# ATSAMV71J21 device description
Architecture: CORTEX-M7; Family: SAMV; Series: SAMV71
Registers are 32-bit, read-write, no defined reset value unless marked. A register's access mark holds for its fields unless they carry their own. Offsets are from the block's base; [hi:lo] are bit positions; {n}, {i} and the like mark numbered series.

## ISI — Image Sensor Interface
Instances: ISI 0x4004C000
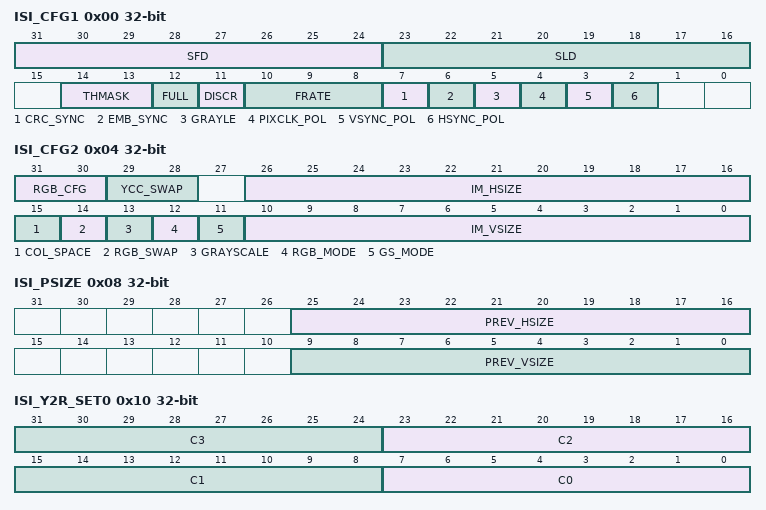
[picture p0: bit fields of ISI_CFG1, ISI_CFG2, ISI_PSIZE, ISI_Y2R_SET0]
0x00 ISI_CFG1 — ISI Configuration 1 Register
  [31:24] SFD — Start of Frame Delay
  [23:16] SLD — Start of Line Delay
  [14:13] THMASK — Threshold Mask
    0=BEATS_4 (Only 4 beats AHB burst allowed); 1=BEATS_8 (Only 4 and 8 beats AHB burst allowed); 2=BEATS_16 (4, 8 and 16 beats AHB burst allowed)
  [12] FULL — Full Mode is Allowed
  [11] DISCR — Disable Codec Request
  [10:8] FRATE — Frame Rate [0..7]
  [7] CRC_SYNC — Embedded Synchronization Correction
  [6] EMB_SYNC — Embedded Synchronization
  [5] GRAYLE — Grayscale Little Endian
  [4] PIXCLK_POL — Pixel Clock Polarity
  [3] VSYNC_POL — Vertical Synchronization Polarity
  [2] HSYNC_POL — Horizontal Synchronization Polarity
0x04 ISI_CFG2 — ISI Configuration 2 Register
  [31:30] RGB_CFG — RGB Pixel Mapping Configuration
    0=DEFAULT (Byte 0 R/G(MSB)Byte 1 G(LSB)/BByte 2 R/G(MSB)Byte 3 G(LSB)/B); 1=MODE1 (Byte 0 B/G(MSB)Byte 1 G(LSB)/RByte 2 B/G(MSB)Byte 3 G(LSB)/R); 2=MODE2 (Byte 0 G(LSB)/RByte 1 B/G(MSB)Byte 2 G(LSB)/RByte 3 B/G(MSB)); 3=MODE3 (Byte 0 G(LSB)/BByte 1 R/G(MSB)Byte 2 G(LSB)/BByte 3 R/G(MSB))
  [29:28] YCC_SWAP — YCrCb Format Swap Mode
    0=DEFAULT (Byte 0 Cb(i)Byte 1 Y(i)Byte 2 Cr(i)Byte 3 Y(i+1)); 1=MODE1 (Byte 0 Cr(i)Byte 1 Y(i)Byte 2 Cb(i)Byte 3 Y(i+1)); 2=MODE2 (Byte 0 Y(i)Byte 1 Cb(i)Byte 2 Y(i+1)Byte 3 Cr(i)); 3=MODE3 (Byte 0 Y(i)Byte 1 Cr(i)Byte 2 Y(i+1)Byte 3 Cb(i))
  [26:16] IM_HSIZE — Horizontal Size of the Image Sensor [0..2047]
  [15] COL_SPACE — Color Space for the Image Data
  [14] RGB_SWAP — RGB Format Swap Mode
  [13] GRAYSCALE — Grayscale Mode Format Enable
  [12] RGB_MODE — RGB Input Mode
  [11] GS_MODE — Grayscale Pixel Format Mode
  [10:0] IM_VSIZE — Vertical Size of the Image Sensor [0..2047]
0x08 ISI_PSIZE — ISI Preview Size Register
  [25:16] PREV_HSIZE — Horizontal Size for the Preview Path
  [9:0] PREV_VSIZE — Vertical Size for the Preview Path
0x0C ISI_PDECF — ISI Preview Decimation Factor Register
  [7:0] DEC_FACTOR — Decimation Factor
0x10 ISI_Y2R_SET0 — ISI Color Space Conversion YCrCb To RGB Set 0 Register
  [8n+7:8n] C{n} (n=0..3) — Color Space Conversion Matrix Coefficient C{n}
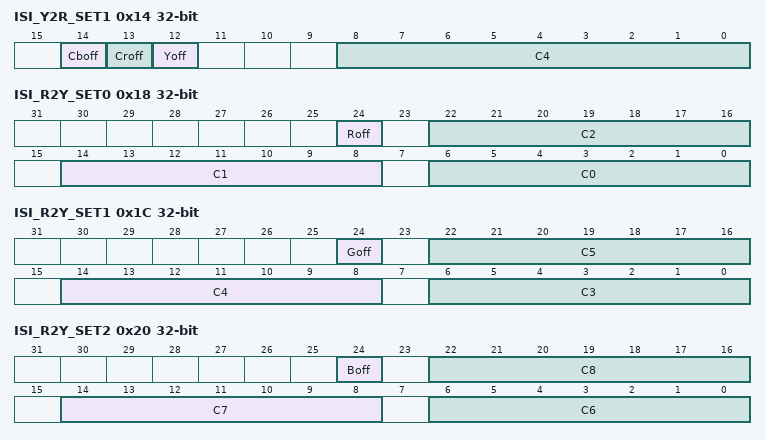
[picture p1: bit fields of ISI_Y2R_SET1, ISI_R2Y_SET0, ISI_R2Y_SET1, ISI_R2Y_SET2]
0x14 ISI_Y2R_SET1 — ISI Color Space Conversion YCrCb To RGB Set 1 Register
  [14] Cboff — Color Space Conversion Blue Chrominance Default Offset
  [13] Croff — Color Space Conversion Red Chrominance Default Offset
  [12] Yoff — Color Space Conversion Luminance Default Offset
  [8:0] C4 — Color Space Conversion Matrix Coefficient C4
0x18 ISI_R2Y_SET0 — ISI Color Space Conversion RGB To YCrCb Set 0 Register
  [24] Roff — Color Space Conversion Red Component Offset
  [22:16] C2 — Color Space Conversion Matrix Coefficient C2
  [14:8] C1 — Color Space Conversion Matrix Coefficient C1
  [6:0] C0 — Color Space Conversion Matrix Coefficient C0
0x1C ISI_R2Y_SET1 — ISI Color Space Conversion RGB To YCrCb Set 1 Register
  [24] Goff — Color Space Conversion Green Component Offset
  [22:16] C5 — Color Space Conversion Matrix Coefficient C5
  [14:8] C4 — Color Space Conversion Matrix Coefficient C4
  [6:0] C3 — Color Space Conversion Matrix Coefficient C3
0x20 ISI_R2Y_SET2 — ISI Color Space Conversion RGB To YCrCb Set 2 Register
  [24] Boff — Color Space Conversion Blue Component Offset
  [22:16] C8 — Color Space Conversion Matrix Coefficient C8
  [14:8] C7 — Color Space Conversion Matrix Coefficient C7
  [6:0] C6 — Color Space Conversion Matrix Coefficient C6
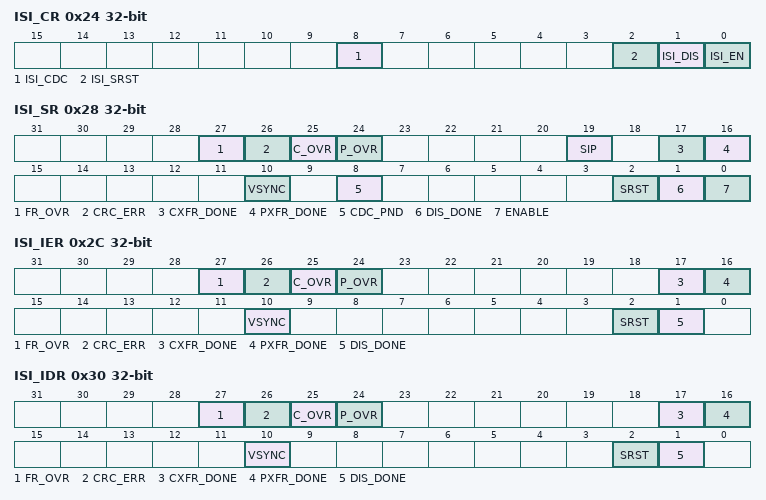
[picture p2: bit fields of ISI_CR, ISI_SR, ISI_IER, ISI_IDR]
0x24 ISI_CR wo — ISI Control Register
  [8] ISI_CDC — ISI Codec Request
  [2] ISI_SRST — ISI Software Reset Request
  [1] ISI_DIS — ISI Module Disable Request
  [0] ISI_EN — ISI Module Enable Request
0x28 ISI_SR ro — ISI Status Register
  [27] FR_OVR — Frame Rate Overrun (cleared on read)
  [26] CRC_ERR — CRC Synchronization Error (cleared on read)
  [25] C_OVR — Codec Datapath Overflow (cleared on read)
  [24] P_OVR — Preview Datapath Overflow (cleared on read)
  [19] SIP — Synchronization in Progress
  [17] CXFR_DONE — Codec DMA Transfer has Terminated (cleared on read)
  [16] PXFR_DONE — Preview DMA Transfer has Terminated (cleared on read)
  [10] VSYNC — Vertical Synchronization (cleared on read)
  [8] CDC_PND — Pending Codec Request
  [2] SRST — Module Software Reset Request has Terminated (cleared on read)
  [1] DIS_DONE — Module Disable Request has Terminated (cleared on read)
  [0] ENABLE — Module Enable
0x2C ISI_IER wo (atomic set of ISI_IMR) — ISI Interrupt Enable Register
  [27] FR_OVR — Frame Rate Overflow Interrupt Enable
  [26] CRC_ERR — Embedded Synchronization CRC Error Interrupt Enable
  [25] C_OVR — Codec Datapath Overflow Interrupt Enable
  [24] P_OVR — Preview Datapath Overflow Interrupt Enable
  [17] CXFR_DONE — Codec DMA Transfer Done Interrupt Enable
  [16] PXFR_DONE — Preview DMA Transfer Done Interrupt Enable
  [10] VSYNC — Vertical Synchronization Interrupt Enable
  [2] SRST — Software Reset Interrupt Enable
  [1] DIS_DONE — Disable Done Interrupt Enable
0x30 ISI_IDR wo (atomic clear of ISI_IMR) — ISI Interrupt Disable Register
  [27] FR_OVR — Frame Rate Overflow Interrupt Disable
  [26] CRC_ERR — Embedded Synchronization CRC Error Interrupt Disable
  [25] C_OVR — Codec Datapath Overflow Interrupt Disable
  [24] P_OVR — Preview Datapath Overflow Interrupt Disable
  [17] CXFR_DONE — Codec DMA Transfer Done Interrupt Disable
  [16] PXFR_DONE — Preview DMA Transfer Done Interrupt Disable
  [10] VSYNC — Vertical Synchronization Interrupt Disable
  [2] SRST — Software Reset Interrupt Disable
  [1] DIS_DONE — Disable Done Interrupt Disable
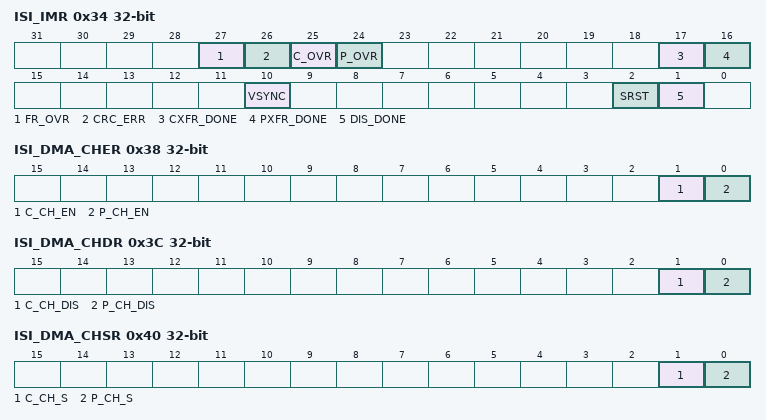
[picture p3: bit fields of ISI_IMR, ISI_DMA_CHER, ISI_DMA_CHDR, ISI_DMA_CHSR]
0x34 ISI_IMR ro (atomic read) — ISI Interrupt Mask Register
  [27] FR_OVR — Frame Rate Overrun
  [26] CRC_ERR — CRC Synchronization Error
  [25] C_OVR — Codec FIFO Overflow
  [24] P_OVR — Preview FIFO Overflow
  [17] CXFR_DONE — Codec DMA Transfer Completed
  [16] PXFR_DONE — Preview DMA Transfer Completed
  [10] VSYNC — Vertical Synchronization
  [2] SRST — Software Reset Completed
  [1] DIS_DONE — Module Disable Operation Completed
0x38 ISI_DMA_CHER wo (atomic set of ISI_DMA_CHSR) — DMA Channel Enable Register
  [1] C_CH_EN — Codec Channel Enable
  [0] P_CH_EN — Preview Channel Enable
0x3C ISI_DMA_CHDR wo (atomic clear of ISI_DMA_CHSR) — DMA Channel Disable Register
  [1] C_CH_DIS — Codec Channel Disable Request
  [0] P_CH_DIS — Preview Channel Disable Request
0x40 ISI_DMA_CHSR ro — DMA Channel Status Register
  [1] C_CH_S — Code DMA Channel Status
  [0] P_CH_S — Preview DMA Channel Status
0x44 ISI_DMA_P_ADDR — DMA Preview Base Address Register
  [31:2] P_ADDR — Preview Image Base Address
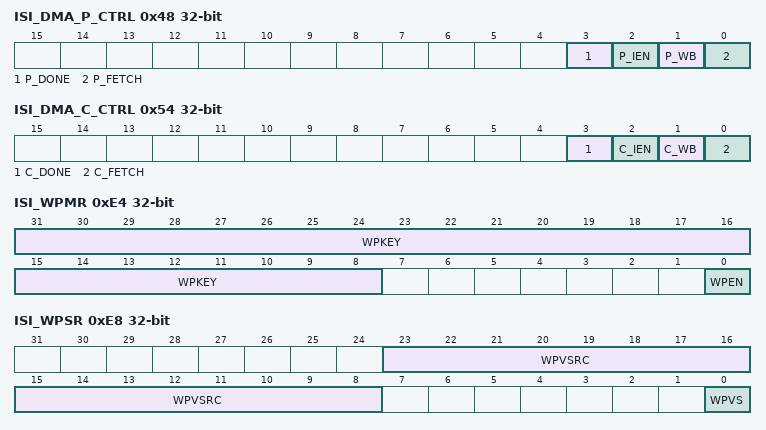
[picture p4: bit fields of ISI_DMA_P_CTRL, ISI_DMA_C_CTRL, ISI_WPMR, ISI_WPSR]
0x48 ISI_DMA_P_CTRL — DMA Preview Control Register
  [3] P_DONE — Preview Transfer Done
  [2] P_IEN — Transfer Done Flag Control
  [1] P_WB — Descriptor Writeback Control Bit
  [0] P_FETCH — Descriptor Fetch Control Bit
0x4C ISI_DMA_P_DSCR — DMA Preview Descriptor Address Register
  [31:2] P_DSCR — Preview Descriptor Base Address
0x50 ISI_DMA_C_ADDR — DMA Codec Base Address Register
  [31:2] C_ADDR — Codec Image Base Address
0x54 ISI_DMA_C_CTRL — DMA Codec Control Register
  [3] C_DONE — Codec Transfer Done
  [2] C_IEN — Transfer Done Flag Control
  [1] C_WB — Descriptor Writeback Control Bit
  [0] C_FETCH — Descriptor Fetch Control Bit
0x58 ISI_DMA_C_DSCR — DMA Codec Descriptor Address Register
  [31:2] C_DSCR — Codec Descriptor Base Address
0xE4 ISI_WPMR — Write Protection Mode Register
  [31:8] WPKEY — Write Protection Key Password
    0x495349=PASSWD (Writing any other value in this field aborts the write operation of the WPEN bit.Always reads as 0.)
  [0] WPEN — Write Protection Enable
0xE8 ISI_WPSR ro — Write Protection Status Register
  [23:8] WPVSRC — Write Protection Violation Source
  [0] WPVS — Write Protection Violation Status
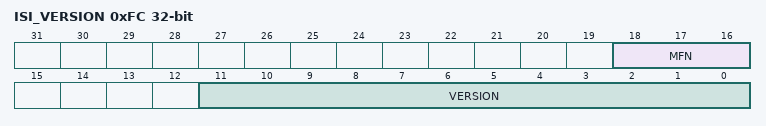
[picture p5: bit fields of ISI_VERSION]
0xFC ISI_VERSION ro — Version Register
  [18:16] MFN — Metal Fix Number
  [11:0] VERSION — Version of the Hardware Module

## Notices in the file
Copyright (c) 2017 Microchip Technology Inc.
SPDX-License-Identifier: Apache-2.0
Licensed under the Apache License, Version 2.0 (the "License");
you may not use this file except in compliance with the License.
You may obtain a copy of the License at
http://www.apache.org/licenses/LICENSE-2.0
Unless required by applicable law or agreed to in writing, software
distributed under the License is distributed on an "AS IS" BASIS,
WITHOUT WARRANTIES OR CONDITIONS OF ANY KIND, either express or implied.
See the License for the specific language governing permissions and
limitations under the License.
